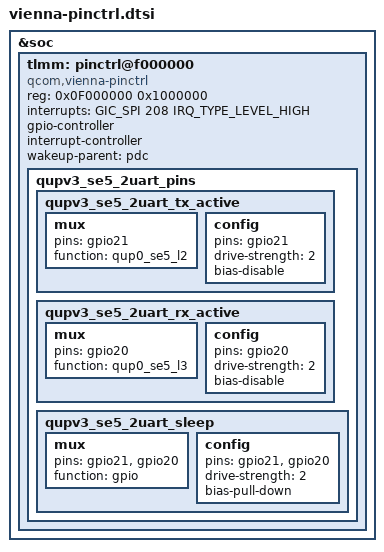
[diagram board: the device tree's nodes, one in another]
// SPDX-License-Identifier: BSD-3-Clause
/*
 *Copyright (c) 2024 Qualcomm Innovation Center, Inc. All rights reserved.
 */

&soc {

	tlmm: pinctrl@f000000 {
		compatible = "qcom,vienna-pinctrl";
		reg = <0x0F000000 0x1000000>;
		interrupts = <GIC_SPI 208 IRQ_TYPE_LEVEL_HIGH>;
		gpio-controller;
		#gpio-cells = <2>;
		interrupt-controller;
		#interrupt-cells = <2>;
		wakeup-parent = <&pdc>;

		qupv3_se5_2uart_pins: qupv3_se5_2uart_pins {
			qupv3_se5_2uart_tx_active: qupv3_se5_2uart_tx_active {
				mux {
					pins = "gpio21";
					function = "qup0_se5_l2";
				};

				config {
					pins = "gpio21";
					drive-strength = <2>;
					bias-disable;
				};
			};

			qupv3_se5_2uart_rx_active: qupv3_se5_2uart_rx_active {
				mux {
					pins = "gpio20";
					function = "qup0_se5_l3";
				};

				config {
					pins = "gpio20";
					drive-strength = <2>;
					bias-disable;
				};
			};

			qupv3_se5_2uart_sleep: qupv3_se5_2uart_sleep {
				mux {
					pins = "gpio21", "gpio20";
					function = "gpio";
				};

				config {
					pins = "gpio21", "gpio20";
					drive-strength = <2>;
					bias-pull-down;
				};
			};
		};
	};
};
